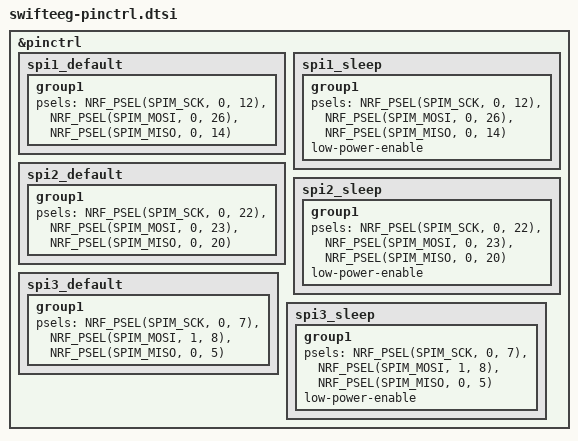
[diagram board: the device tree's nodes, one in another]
/*
 * Pin assignments taken from SwiftEEG.kicad_sch / .kicad_pcb.
 * SPI instance choice matters: only SPIM3 exceeds 8 MHz on nRF52840,
 * so the ADS1299 must own SPI3.
 */
&pinctrl {
	/* SD card — SPI mode only, 4-bit SDIO is not wired */
	spi1_default: spi1_default {
		group1 {
			psels = <NRF_PSEL(SPIM_SCK, 0, 12)>,
				<NRF_PSEL(SPIM_MOSI, 0, 26)>,
				<NRF_PSEL(SPIM_MISO, 0, 14)>;
		};
	};
	spi1_sleep: spi1_sleep {
		group1 {
			psels = <NRF_PSEL(SPIM_SCK, 0, 12)>,
				<NRF_PSEL(SPIM_MOSI, 0, 26)>,
				<NRF_PSEL(SPIM_MISO, 0, 14)>;
			low-power-enable;
		};
	};

	/* LSM6DSV16X IMU */
	spi2_default: spi2_default {
		group1 {
			psels = <NRF_PSEL(SPIM_SCK, 0, 22)>,
				<NRF_PSEL(SPIM_MOSI, 0, 23)>,
				<NRF_PSEL(SPIM_MISO, 0, 20)>;
		};
	};
	spi2_sleep: spi2_sleep {
		group1 {
			psels = <NRF_PSEL(SPIM_SCK, 0, 22)>,
				<NRF_PSEL(SPIM_MOSI, 0, 23)>,
				<NRF_PSEL(SPIM_MISO, 0, 20)>;
			low-power-enable;
		};
	};

	/* ADS1299 AFE — SPIM3, the only instance that can exceed 8 MHz */
	spi3_default: spi3_default {
		group1 {
			psels = <NRF_PSEL(SPIM_SCK, 0, 7)>,
				<NRF_PSEL(SPIM_MOSI, 1, 8)>,
				<NRF_PSEL(SPIM_MISO, 0, 5)>;
		};
	};
	spi3_sleep: spi3_sleep {
		group1 {
			psels = <NRF_PSEL(SPIM_SCK, 0, 7)>,
				<NRF_PSEL(SPIM_MOSI, 1, 8)>,
				<NRF_PSEL(SPIM_MISO, 0, 5)>;
			low-power-enable;
		};
	};
};
